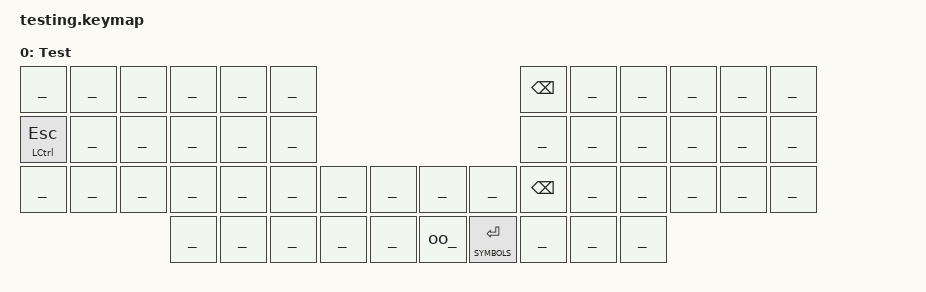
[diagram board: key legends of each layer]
/ {
    keymap {
        compatible = "zmk,keymap";
        experimental {
            label = "Test";
            bindings = <
//                ╭─────────┬─────┬─────┬─────┬─────┬─────╮                                       ╭─────┬─────┬─────┬─────┬─────┬─────╮
//                │         │     │     │     │     │     │                                       │  ⌫  │     │     │     │     │     │
//                ├─────────┼─────┼─────┼─────┼─────┼─────┤                                       ├─────┼─────┼─────┼─────┼─────┼─────┤
//                │  ⌃ │ ⎋  │     │     │     │     │     │                                       │     │     │     │     │     │     │
//                ├─────────┼─────┼─────┼─────┼─────┼─────┼─────┬─────╮   ╭─────┬─────────────────┼─────┼─────┼─────┼─────┼─────┼─────┤
//                │         │     │     │     │     │     │     │     │   │     │                 │  ⌫  │     │     │     │     │     │
//                ╰─────────┴─────┴─────┼─────┼─────┼─────┼─────┼─────┤   ├─────┼─────────────────┼─────┼─────┼─────┼─────┴─────┴─────╯
//                                      │     │     │     │     │     │   │ --- │ &lt SYMBOLS  ⏎  │     │     │     │                  
//                                      ╰─────┴─────┴─────┴─────┴─────╯   ╰─────┴─────────────────┴─────┴─────┴─────╯                  
              ____            ____   ____   ____   ____   ____                                              &kp BSPC   ____   ____   ____   ____   ____
              &mt LCTRL ESC   ____   ____   ____   ____   ____                                              ____       ____   ____   ____   ____   ____
              ____            ____   ____   ____   ____   ____   ____   ____       ____   ____              &kp BSPC   ____   ____   ____   ____   ____
                                            ____   ____   ____   ____   ____       _oo_   &lt SYMBOLS RET   ____       ____   ____                     
            >;
        };
	};
};
